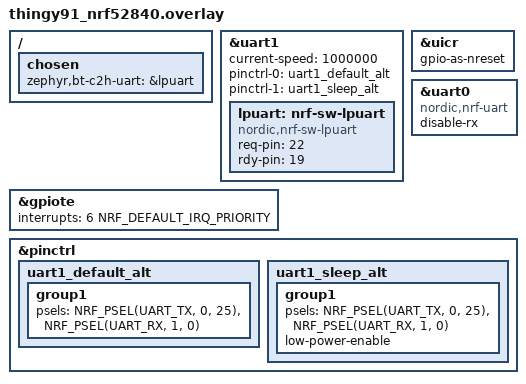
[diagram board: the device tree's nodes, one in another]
/* SPDX-License-Identifier: LicenseRef-Nordic-5-Clause */

/ {
	chosen {
		zephyr,bt-c2h-uart=&lpuart;
	};
};

&uart1 {
	current-speed = <1000000>;
	status = "okay";

	pinctrl-0 = <&uart1_default_alt>;
	pinctrl-1 = <&uart1_sleep_alt>;
	pinctrl-names = "default", "sleep";
	lpuart: nrf-sw-lpuart {
		compatible = "nordic,nrf-sw-lpuart";
		status = "okay";
		req-pin = <22>;
		rdy-pin = <19>;
	};
};

&uicr {
	gpio-as-nreset;
};

&gpiote {
	interrupts = <6 NRF_DEFAULT_IRQ_PRIORITY>;
};

/* Disabling uart rx pin to get low power */
&uart0 {
	compatible = "nordic,nrf-uart";
	disable-rx;
};

&pinctrl {
	uart1_default_alt: uart1_default_alt {
		group1 {
			psels = <NRF_PSEL(UART_TX, 0, 25)>,
				<NRF_PSEL(UART_RX, 1, 0)>;
		};
	};

	uart1_sleep_alt: uart1_sleep_alt {
		group1 {
			psels = <NRF_PSEL(UART_TX, 0, 25)>,
				<NRF_PSEL(UART_RX, 1, 0)>;
			low-power-enable;
		};
	};
};
